# timer: IP-XACT component
VLNV Synopsys::timer:2.0
A programmable interval timer as part of the Freescale mmc2001 microcontroller.

## Address spaces and blocks
r_registers.r_registers: base 0x0, range 12, width 32, register

## Registers
Registers are 32-bit, read-write, no defined reset value unless marked. A register's access mark holds for its fields unless they carry their own. Offsets are from the block's base; lines under a group give offsets from that group; [hi:lo] are bit positions; {n}, {i} and the like mark numbered series; 'fields as' and 'values as' point back to an identical list; <NAME> marks a mode.

## r_registers.r_registers — The register interface
Base 0x00000000
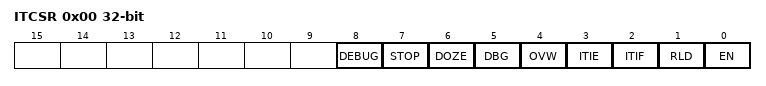
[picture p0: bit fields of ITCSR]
0x00 ITCSR — Interval Timer Control/Status Register
  [8] DEBUG — The debug flag.
  [7] STOP — Stop Mode Control. This bit controls the function of the PIT in stop mode: 0 = PIT function is not affected in stop mode 1 = PIT function is frozen in stop mode
  [6] DOZE — Doze Mode Control. This bit controls the function of the PIT in doze mode: 0 = PIT function is not affected in doze mode 1 = PIT function is frozen in doze mode
  [5] DBG — Debug Mode Control. This bit controls the function of the PIT in debug mode: 0 = PIT function is not affected in debug mode 1 = PIT function is frozen in debug mode
  [4] OVW — Counter Overwrite Enable. This bit controls what happens to the counter value when the modulus latch is written: 0 = Modulus latch is a holding register for values to be loaded into the counter when the count expires to zero. 1 = Modulus latch is transparent. All writes to the latch will also overwrite the counter contents.
  [3] ITIE — Interval Timer Interrupt Enable. This bit controls the PIT interrupt function: 0 = ITIF is inhibited from reaching the CPU. 1 = ITIF is allowed to request an interrupt.
  [2] ITIF — Interval Timer Interrupt Flag. This bit is the PIT interrupt flag. It is cleared by writing a one to this bit or by writing to the PIT data register: 0 = No PIT interrupt is present 1 = PIT interrupt is present.
  [1] RLD — Counter Reload Control. This bit controls whether the value contained in the modulus latch is reloaded into the counter when the counter reaches a count of zero or whether the counter rolls over from zero to 0xFFFF: 0 = Counter rolls over to 0xFFFF 1 = Counter is reloaded from the modulus latch
  [0] EN — Enable Timer. This bit controls the PIT enable function: 0 = PIT is disabled 1 = PIT is enabled
0x04 ITDR — Interval Timer Data Register
0x08 ITADR — Interval Timer Alternate Data Register
